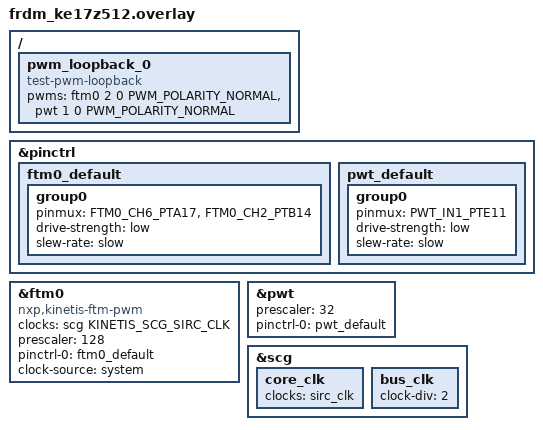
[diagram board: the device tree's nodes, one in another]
/*
 * Copyright 2024 NXP
 *
 * SPDX-License-Identifier: Apache-2.0
 */

&pinctrl {
	ftm0_default: ftm0_default {
		group0 {
			pinmux = <FTM0_CH6_PTA17>,
				<FTM0_CH2_PTB14>;
			drive-strength = "low";
			slew-rate = "slow";
		};
	};

	pwt_default: pwt_default {
		group0 {
			pinmux = <PWT_IN1_PTE11>;
			drive-strength = "low";
			slew-rate = "slow";
		};
	};
};

/* To test this sample, connect
 * PTB14(J3-11) ---> PTE11(J2-11)
 */

/ {
	pwm_loopback_0 {
		compatible = "test-pwm-loopback";
		pwms = <&ftm0 2 0 PWM_POLARITY_NORMAL>, /* PTB14 J3 pin 11 */
			<&pwt 1 0 PWM_POLARITY_NORMAL>; /* PTE11 J2 pin 11 */
	};
};

&ftm0 {
	status = "okay";
	compatible = "nxp,kinetis-ftm-pwm";
	clocks = <&scg KINETIS_SCG_SIRC_CLK>;
	prescaler = <128>;
	#pwm-cells = <3>;
	pinctrl-0 = <&ftm0_default>;
	pinctrl-names = "default";
	clock-source = "system";
};

&pwt {
	status = "okay";
	prescaler = <32>;
	pinctrl-0 = <&pwt_default>;
	pinctrl-names = "default";
};

&scg {
	core_clk {
		clocks = <&sirc_clk>;
	};

	bus_clk {
		clock-div = <2>;
	};
};
